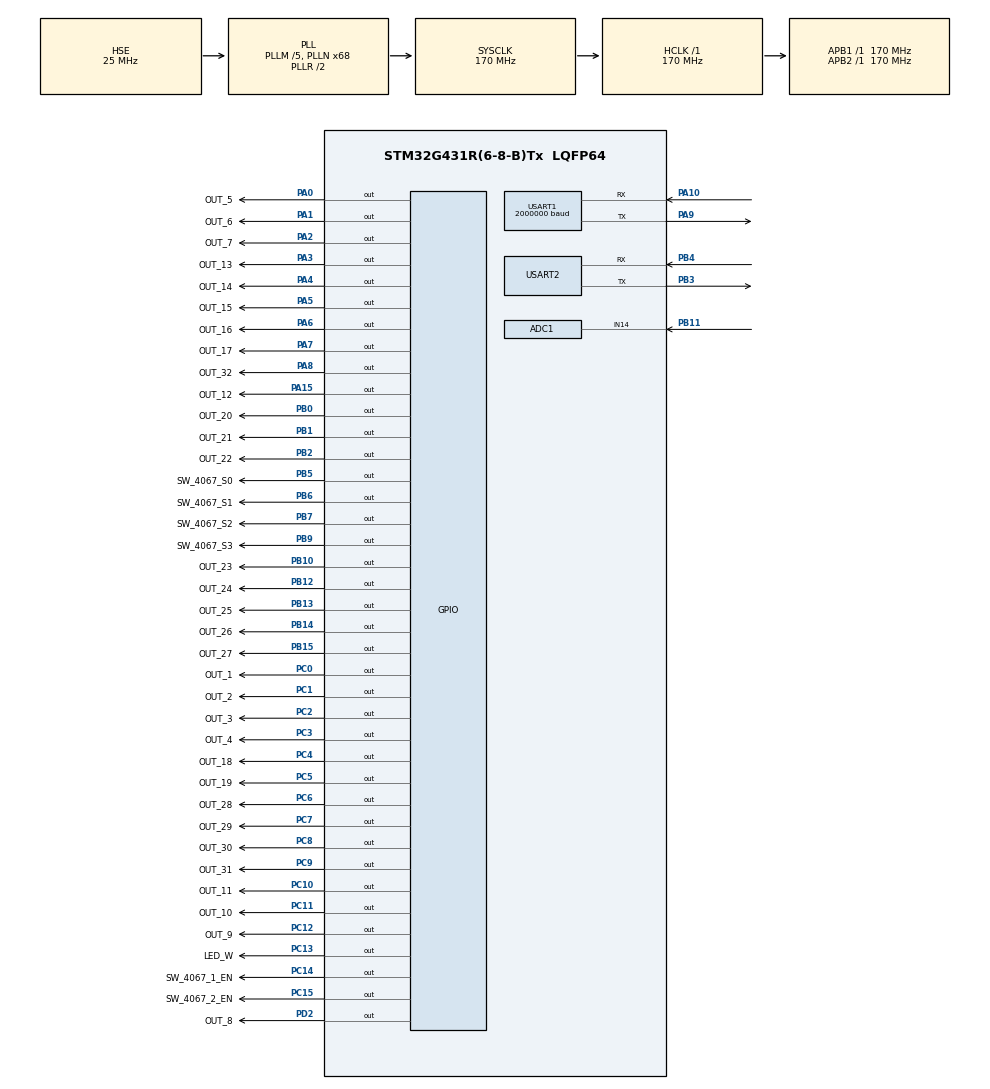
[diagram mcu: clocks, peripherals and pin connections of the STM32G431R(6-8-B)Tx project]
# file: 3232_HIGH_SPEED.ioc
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ADC1.Channel-0\#ChannelRegularConversion=ADC_CHANNEL_14
ADC1.ContinuousConvMode=ENABLE
ADC1.DMAContinuousRequests=ENABLE
ADC1.NbrOfConversionFlag=1
ADC1.OffsetNumber-0\#ChannelRegularConversion=ADC_OFFSET_NONE
ADC1.Rank-0\#ChannelRegularConversion=1
ADC1.Resolution=ADC_RESOLUTION_8B
ADC1.SamplingTime-0\#ChannelRegularConversion=ADC_SAMPLETIME_2CYCLES_5
ADC1.master=1
Dma.ADC1.3.Direction=DMA_PERIPH_TO_MEMORY
Dma.ADC1.3.EventEnable=DISABLE
Dma.ADC1.3.Instance=DMA1_Channel4
Dma.ADC1.3.MemDataAlignment=DMA_MDATAALIGN_BYTE
Dma.ADC1.3.MemInc=DMA_MINC_ENABLE
Dma.ADC1.3.Mode=DMA_CIRCULAR
Dma.ADC1.3.PeriphDataAlignment=DMA_PDATAALIGN_BYTE
Dma.ADC1.3.PeriphInc=DMA_PINC_DISABLE
Dma.ADC1.3.Polarity=HAL_DMAMUX_REQ_GEN_RISING
Dma.ADC1.3.Priority=DMA_PRIORITY_LOW
Dma.ADC1.3.RequestNumber=1
Dma.ADC1.3.SignalID=NONE
Dma.ADC1.3.SyncEnable=DISABLE
Dma.ADC1.3.SyncPolarity=HAL_DMAMUX_SYNC_NO_EVENT
Dma.ADC1.3.SyncRequestNumber=1
Dma.ADC1.3.SyncSignalID=NONE
Dma.Request0=USART2_RX
Dma.Request1=USART2_TX
Dma.Request2=USART1_TX
Dma.Request3=ADC1
Dma.USART1_TX.2.Direction=DMA_MEMORY_TO_PERIPH
Dma.USART1_TX.2.EventEnable=DISABLE
Dma.USART1_TX.2.Instance=DMA1_Channel3
Dma.USART1_TX.2.MemDataAlignment=DMA_MDATAALIGN_BYTE
Dma.USART1_TX.2.MemInc=DMA_MINC_ENABLE
Dma.USART1_TX.2.Mode=DMA_NORMAL
Dma.USART1_TX.2.PeriphDataAlignment=DMA_PDATAALIGN_BYTE
Dma.USART1_TX.2.PeriphInc=DMA_PINC_DISABLE
Dma.USART1_TX.2.Polarity=HAL_DMAMUX_REQ_GEN_RISING
Dma.USART1_TX.2.Priority=DMA_PRIORITY_LOW
Dma.USART1_TX.2.RequestNumber=1
Dma.USART1_TX.2.SignalID=NONE
Dma.USART1_TX.2.SyncEnable=DISABLE
Dma.USART1_TX.2.SyncPolarity=HAL_DMAMUX_SYNC_NO_EVENT
Dma.USART1_TX.2.SyncRequestNumber=1
Dma.USART1_TX.2.SyncSignalID=NONE
Dma.USART2_RX.0.Direction=DMA_PERIPH_TO_MEMORY
Dma.USART2_RX.0.EventEnable=DISABLE
Dma.USART2_RX.0.Instance=DMA1_Channel1
Dma.USART2_RX.0.MemDataAlignment=DMA_MDATAALIGN_BYTE
Dma.USART2_RX.0.MemInc=DMA_MINC_ENABLE
Dma.USART2_RX.0.Mode=DMA_NORMAL
Dma.USART2_RX.0.PeriphDataAlignment=DMA_PDATAALIGN_BYTE
Dma.USART2_RX.0.PeriphInc=DMA_PINC_DISABLE
Dma.USART2_RX.0.Polarity=HAL_DMAMUX_REQ_GEN_RISING
Dma.USART2_RX.0.Priority=DMA_PRIORITY_LOW
Dma.USART2_RX.0.RequestNumber=1
Dma.USART2_RX.0.SignalID=NONE
Dma.USART2_RX.0.SyncEnable=DISABLE
Dma.USART2_RX.0.SyncPolarity=HAL_DMAMUX_SYNC_NO_EVENT
Dma.USART2_RX.0.SyncRequestNumber=1
Dma.USART2_RX.0.SyncSignalID=NONE
Dma.USART2_TX.1.Direction=DMA_MEMORY_TO_PERIPH
Dma.USART2_TX.1.EventEnable=DISABLE
Dma.USART2_TX.1.Instance=DMA1_Channel2
Dma.USART2_TX.1.MemDataAlignment=DMA_MDATAALIGN_BYTE
Dma.USART2_TX.1.MemInc=DMA_MINC_ENABLE
Dma.USART2_TX.1.Mode=DMA_NORMAL
Dma.USART2_TX.1.PeriphDataAlignment=DMA_PDATAALIGN_BYTE
Dma.USART2_TX.1.PeriphInc=DMA_PINC_DISABLE
Dma.USART2_TX.1.Polarity=HAL_DMAMUX_REQ_GEN_RISING
Dma.USART2_TX.1.Priority=DMA_PRIORITY_LOW
Dma.USART2_TX.1.RequestNumber=1
Dma.USART2_TX.1.SignalID=NONE
Dma.USART2_TX.1.SyncEnable=DISABLE
Dma.USART2_TX.1.SyncPolarity=HAL_DMAMUX_SYNC_NO_EVENT
Dma.USART2_TX.1.SyncRequestNumber=1
Dma.USART2_TX.1.SyncSignalID=NONE
IWDG.Prescaler=IWDG_PRESCALER_128
Mcu.Family=STM32G4
Mcu.Name=STM32G431R(6-8-B)Tx
Mcu.Package=LQFP64
NVIC.DMA1_Channel1_IRQn=true\:0\:0\:false\:false\:true\:false\:true\:true
NVIC.DMA1_Channel2_IRQn=true\:0\:0\:false\:false\:true\:false\:true\:true
NVIC.DMA1_Channel3_IRQn=true\:0\:0\:false\:false\:true\:false\:true\:true
NVIC.DMA1_Channel4_IRQn=true\:0\:0\:false\:false\:true\:false\:true\:true
NVIC.PriorityGroup=NVIC_PRIORITYGROUP_4
NVIC.USART1_IRQn=true\:0\:0\:false\:false\:true\:false\:true\:true
NVIC.USART2_IRQn=true\:0\:0\:false\:false\:true\:false\:true\:true
PA0.GPIO_Label=OUT_5
PA0.GPIO_ModeDefaultOutputPP=GPIO_MODE_OUTPUT_PP
PA0.GPIO_PuPd=GPIO_NOPULL
PA0.GPIO_Speed=GPIO_SPEED_FREQ_VERY_HIGH
PA0.PinState=GPIO_PIN_RESET
PA0.Signal=GPIO_Output
PA1.GPIO_Label=OUT_6
PA1.GPIO_ModeDefaultOutputPP=GPIO_MODE_OUTPUT_PP
PA1.GPIO_PuPd=GPIO_NOPULL
PA1.GPIO_Speed=GPIO_SPEED_FREQ_VERY_HIGH
PA1.PinState=GPIO_PIN_RESET
PA1.Signal=GPIO_Output
PA10.GPIO_Speed=GPIO_SPEED_FREQ_VERY_HIGH
PA10.Mode=Asynchronous
PA10.Signal=USART1_RX
PA13.Mode=Serial_Wire
PA13.Signal=SYS_JTMS-SWDIO
PA14.Mode=Serial_Wire
PA14.Signal=SYS_JTCK-SWCLK
PA15.GPIO_Label=OUT_12
PA15.GPIO_ModeDefaultOutputPP=GPIO_MODE_OUTPUT_PP
PA15.GPIO_PuPd=GPIO_NOPULL
PA15.GPIO_Speed=GPIO_SPEED_FREQ_VERY_HIGH
PA15.PinState=GPIO_PIN_RESET
PA15.Signal=GPIO_Output
PA2.GPIO_Label=OUT_7
PA2.GPIO_ModeDefaultOutputPP=GPIO_MODE_OUTPUT_PP
PA2.GPIO_PuPd=GPIO_NOPULL
PA2.GPIO_Speed=GPIO_SPEED_FREQ_VERY_HIGH
PA2.PinState=GPIO_PIN_RESET
PA2.Signal=GPIO_Output
PA3.GPIO_Label=OUT_13
PA3.GPIO_ModeDefaultOutputPP=GPIO_MODE_OUTPUT_PP
PA3.GPIO_PuPd=GPIO_NOPULL
PA3.GPIO_Speed=GPIO_SPEED_FREQ_VERY_HIGH
PA3.PinState=GPIO_PIN_RESET
PA3.Signal=GPIO_Output
PA4.GPIO_Label=OUT_14
PA4.GPIO_ModeDefaultOutputPP=GPIO_MODE_OUTPUT_PP
PA4.GPIO_PuPd=GPIO_NOPULL
PA4.GPIO_Speed=GPIO_SPEED_FREQ_VERY_HIGH
PA4.PinState=GPIO_PIN_RESET
PA4.Signal=GPIO_Output
PA5.GPIO_Label=OUT_15
PA5.GPIO_ModeDefaultOutputPP=GPIO_MODE_OUTPUT_PP
PA5.GPIO_PuPd=GPIO_NOPULL
PA5.GPIO_Speed=GPIO_SPEED_FREQ_VERY_HIGH
PA5.PinState=GPIO_PIN_RESET
PA5.Signal=GPIO_Output
PA6.GPIO_Label=OUT_16
PA6.GPIO_ModeDefaultOutputPP=GPIO_MODE_OUTPUT_PP
PA6.GPIO_PuPd=GPIO_NOPULL
PA6.GPIO_Speed=GPIO_SPEED_FREQ_VERY_HIGH
PA6.PinState=GPIO_PIN_RESET
PA6.Signal=GPIO_Output
PA7.GPIO_Label=OUT_17
PA7.GPIO_ModeDefaultOutputPP=GPIO_MODE_OUTPUT_PP
PA7.GPIO_PuPd=GPIO_NOPULL
PA7.GPIO_Speed=GPIO_SPEED_FREQ_VERY_HIGH
PA7.PinState=GPIO_PIN_RESET
PA7.Signal=GPIO_Output
PA8.GPIO_Label=OUT_32
PA8.GPIO_ModeDefaultOutputPP=GPIO_MODE_OUTPUT_PP
PA8.GPIO_PuPd=GPIO_NOPULL
PA8.GPIO_Speed=GPIO_SPEED_FREQ_VERY_HIGH
PA8.PinState=GPIO_PIN_RESET
PA8.Signal=GPIO_Output
PA9.GPIO_Speed=GPIO_SPEED_FREQ_VERY_HIGH
PA9.Mode=Asynchronous
PA9.Signal=USART1_TX
PB0.GPIO_Label=OUT_20
PB0.GPIO_ModeDefaultOutputPP=GPIO_MODE_OUTPUT_PP
PB0.GPIO_PuPd=GPIO_NOPULL
PB0.GPIO_Speed=GPIO_SPEED_FREQ_VERY_HIGH
PB0.PinState=GPIO_PIN_RESET
PB0.Signal=GPIO_Output
PB1.GPIO_Label=OUT_21
PB1.GPIO_ModeDefaultOutputPP=GPIO_MODE_OUTPUT_PP
PB1.GPIO_PuPd=GPIO_NOPULL
PB1.GPIO_Speed=GPIO_SPEED_FREQ_VERY_HIGH
PB1.PinState=GPIO_PIN_RESET
PB1.Signal=GPIO_Output
PB10.GPIO_Label=OUT_23
PB10.GPIO_ModeDefaultOutputPP=GPIO_MODE_OUTPUT_PP
PB10.GPIO_PuPd=GPIO_NOPULL
PB10.GPIO_Speed=GPIO_SPEED_FREQ_VERY_HIGH
PB10.PinState=GPIO_PIN_RESET
PB10.Signal=GPIO_Output
PB11.Mode=IN14-Single-Ended
PB11.Signal=ADC1_IN14
PB12.GPIO_Label=OUT_24
PB12.GPIO_ModeDefaultOutputPP=GPIO_MODE_OUTPUT_PP
PB12.GPIO_PuPd=GPIO_NOPULL
PB12.GPIO_Speed=GPIO_SPEED_FREQ_VERY_HIGH
PB12.PinState=GPIO_PIN_RESET
PB12.Signal=GPIO_Output
PB13.GPIO_Label=OUT_25
PB13.GPIO_ModeDefaultOutputPP=GPIO_MODE_OUTPUT_PP
PB13.GPIO_PuPd=GPIO_NOPULL
PB13.GPIO_Speed=GPIO_SPEED_FREQ_VERY_HIGH
PB13.PinState=GPIO_PIN_RESET
PB13.Signal=GPIO_Output
PB14.GPIO_Label=OUT_26
PB14.GPIO_ModeDefaultOutputPP=GPIO_MODE_OUTPUT_PP
PB14.GPIO_PuPd=GPIO_NOPULL
PB14.GPIO_Speed=GPIO_SPEED_FREQ_VERY_HIGH
PB14.PinState=GPIO_PIN_RESET
PB14.Signal=GPIO_Output
PB15.GPIO_Label=OUT_27
PB15.GPIO_ModeDefaultOutputPP=GPIO_MODE_OUTPUT_PP
PB15.GPIO_PuPd=GPIO_NOPULL
PB15.GPIO_Speed=GPIO_SPEED_FREQ_VERY_HIGH
PB15.PinState=GPIO_PIN_RESET
PB15.Signal=GPIO_Output
PB2.GPIO_Label=OUT_22
PB2.GPIO_ModeDefaultOutputPP=GPIO_MODE_OUTPUT_PP
PB2.GPIO_PuPd=GPIO_NOPULL
PB2.GPIO_Speed=GPIO_SPEED_FREQ_VERY_HIGH
PB2.PinState=GPIO_PIN_RESET
PB2.Signal=GPIO_Output
PB3.GPIO_Speed=GPIO_SPEED_FREQ_VERY_HIGH
PB3.Mode=Asynchronous
PB3.Signal=USART2_TX
PB4.GPIO_Speed=GPIO_SPEED_FREQ_VERY_HIGH
PB4.Mode=Asynchronous
PB4.Signal=USART2_RX
PB5.GPIO_Label=SW_4067_S0
PB5.Signal=GPIO_Output
PB6.GPIO_Label=SW_4067_S1
PB6.Signal=GPIO_Output
PB7.GPIO_Label=SW_4067_S2
PB7.Signal=GPIO_Output
PB9.GPIO_Label=SW_4067_S3
PB9.Signal=GPIO_Output
PC0.GPIO_Label=OUT_1
PC0.GPIO_ModeDefaultOutputPP=GPIO_MODE_OUTPUT_PP
PC0.GPIO_PuPd=GPIO_NOPULL
PC0.GPIO_Speed=GPIO_SPEED_FREQ_VERY_HIGH
PC0.PinState=GPIO_PIN_RESET
PC0.Signal=GPIO_Output
PC1.GPIO_Label=OUT_2
PC1.GPIO_ModeDefaultOutputPP=GPIO_MODE_OUTPUT_PP
PC1.GPIO_PuPd=GPIO_NOPULL
PC1.GPIO_Speed=GPIO_SPEED_FREQ_VERY_HIGH
PC1.PinState=GPIO_PIN_RESET
PC1.Signal=GPIO_Output
PC10.GPIO_Label=OUT_11
PC10.GPIO_ModeDefaultOutputPP=GPIO_MODE_OUTPUT_PP
PC10.GPIO_PuPd=GPIO_NOPULL
PC10.GPIO_Speed=GPIO_SPEED_FREQ_VERY_HIGH
PC10.PinState=GPIO_PIN_RESET
PC10.Signal=GPIO_Output
PC11.GPIO_Label=OUT_10
PC11.GPIO_ModeDefaultOutputPP=GPIO_MODE_OUTPUT_PP
PC11.GPIO_PuPd=GPIO_NOPULL
PC11.GPIO_Speed=GPIO_SPEED_FREQ_VERY_HIGH
PC11.PinState=GPIO_PIN_RESET
PC11.Signal=GPIO_Output
PC12.GPIO_Label=OUT_9
PC12.GPIO_ModeDefaultOutputPP=GPIO_MODE_OUTPUT_PP
PC12.GPIO_PuPd=GPIO_NOPULL
PC12.GPIO_Speed=GPIO_SPEED_FREQ_VERY_HIGH
PC12.PinState=GPIO_PIN_RESET
PC12.Signal=GPIO_Output
PC13.GPIO_Label=LED_W
PC13.Signal=GPIO_Output
PC14-OSC32_IN.GPIO_Label=SW_4067_1_EN
PC14-OSC32_IN.Signal=GPIO_Output
PC15-OSC32_OUT.GPIO_Label=SW_4067_2_EN
PC15-OSC32_OUT.Signal=GPIO_Output
PC2.GPIO_Label=OUT_3
PC2.GPIO_ModeDefaultOutputPP=GPIO_MODE_OUTPUT_PP
PC2.GPIO_PuPd=GPIO_NOPULL
PC2.GPIO_Speed=GPIO_SPEED_FREQ_VERY_HIGH
PC2.PinState=GPIO_PIN_RESET
PC2.Signal=GPIO_Output
PC3.GPIO_Label=OUT_4
PC3.GPIO_ModeDefaultOutputPP=GPIO_MODE_OUTPUT_PP
PC3.GPIO_PuPd=GPIO_NOPULL
PC3.GPIO_Speed=GPIO_SPEED_FREQ_VERY_HIGH
PC3.PinState=GPIO_PIN_RESET
PC3.Signal=GPIO_Output
PC4.GPIO_Label=OUT_18
PC4.GPIO_ModeDefaultOutputPP=GPIO_MODE_OUTPUT_PP
PC4.GPIO_PuPd=GPIO_NOPULL
PC4.GPIO_Speed=GPIO_SPEED_FREQ_VERY_HIGH
PC4.PinState=GPIO_PIN_RESET
PC4.Signal=GPIO_Output
PC5.GPIO_Label=OUT_19
PC5.GPIO_ModeDefaultOutputPP=GPIO_MODE_OUTPUT_PP
PC5.GPIO_PuPd=GPIO_NOPULL
PC5.GPIO_Speed=GPIO_SPEED_FREQ_VERY_HIGH
PC5.PinState=GPIO_PIN_RESET
PC5.Signal=GPIO_Output
PC6.GPIO_Label=OUT_28
PC6.GPIO_ModeDefaultOutputPP=GPIO_MODE_OUTPUT_PP
PC6.GPIO_PuPd=GPIO_NOPULL
PC6.GPIO_Speed=GPIO_SPEED_FREQ_VERY_HIGH
PC6.PinState=GPIO_PIN_RESET
PC6.Signal=GPIO_Output
PC7.GPIO_Label=OUT_29
PC7.GPIO_ModeDefaultOutputPP=GPIO_MODE_OUTPUT_PP
PC7.GPIO_PuPd=GPIO_NOPULL
PC7.GPIO_Speed=GPIO_SPEED_FREQ_VERY_HIGH
PC7.PinState=GPIO_PIN_RESET
PC7.Signal=GPIO_Output
PC8.GPIO_Label=OUT_30
PC8.GPIO_ModeDefaultOutputPP=GPIO_MODE_OUTPUT_PP
PC8.GPIO_PuPd=GPIO_NOPULL
PC8.GPIO_Speed=GPIO_SPEED_FREQ_VERY_HIGH
PC8.PinState=GPIO_PIN_RESET
PC8.Signal=GPIO_Output
PC9.GPIO_Label=OUT_31
PC9.GPIO_ModeDefaultOutputPP=GPIO_MODE_OUTPUT_PP
PC9.GPIO_PuPd=GPIO_NOPULL
PC9.GPIO_Speed=GPIO_SPEED_FREQ_VERY_HIGH
PC9.PinState=GPIO_PIN_RESET
PC9.Signal=GPIO_Output
PD2.GPIO_Label=OUT_8
PD2.GPIO_ModeDefaultOutputPP=GPIO_MODE_OUTPUT_PP
PD2.GPIO_PuPd=GPIO_NOPULL
PD2.GPIO_Speed=GPIO_SPEED_FREQ_VERY_HIGH
PD2.PinState=GPIO_PIN_RESET
PD2.Signal=GPIO_Output
PF0-OSC_IN.Mode=HSE-External-Oscillator
PF0-OSC_IN.Signal=RCC_OSC_IN
PF1-OSC_OUT.Mode=HSE-External-Oscillator
PF1-OSC_OUT.Signal=RCC_OSC_OUT
ProjectManager.HeapSize=0x200
ProjectManager.StackSize=0x400
ProjectManager.TargetToolchain=MDK-ARM V5.32
RCC.ADC12Freq_Value=170000000
RCC.AHBFreq_Value=170000000
RCC.APB1Freq_Value=170000000
RCC.APB1TimFreq_Value=170000000
RCC.APB2Freq_Value=170000000
RCC.APB2TimFreq_Value=170000000
RCC.CortexFreq_Value=170000000
RCC.EXTERNAL_CLOCK_VALUE=12288000
RCC.HCLKFreq_Value=170000000
RCC.HSE_VALUE=25000000
RCC.HSI48_VALUE=48000000
RCC.HSI_VALUE=16000000
RCC.LSE_VALUE=32768
RCC.PLLM=RCC_PLLM_DIV5
RCC.PLLN=68
RCC.PLLSourceVirtual=RCC_PLLSOURCE_HSE
RCC.SYSCLKFreq_VALUE=170000000
RCC.SYSCLKSource=RCC_SYSCLKSOURCE_PLLCLK
RCC.USBFreq_Value=170000000
RCC.VCOOutputFreq_Value=340000000
USART1.BaudRate=2000000
USART1.VirtualMode-Asynchronous=VM_ASYNC
USART2.VirtualMode-Asynchronous=VM_ASYNC
VP_IWDG_VS_IWDG.Mode=IWDG_Activate
VP_SYS_VS_DBSignals.Mode=DisableDeadBatterySignals
board=custom

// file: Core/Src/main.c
/* USER CODE BEGIN Header */
/**
 ******************************************************************************
 * @file           : main.c
 * @brief          : Main program body
 ******************************************************************************
 * @attention
 *
 * Copyright (c) 2025 STMicroelectronics.
 * All rights reserved.
 *
 * This software is licensed under terms that can be found in the LICENSE file
 * in the root directory of this software component.
 * If no LICENSE file comes with this software, it is provided AS-IS.
 *
 ******************************************************************************
 */
/* USER CODE END Header */
#include "main.h"
#include "adc.h"
#include "dma.h"
#include "iwdg.h"
#include "usart.h"
#include "gpio.h"

/* USER CODE BEGIN Includes */
#include "user_comm.h"
/* USER CODE END Includes */

void SystemClock_Config(void);

int main(void)
{

    /* MCU Configuration--------------------------------------------------------*/

    /* Reset of all peripherals, Initializes the Flash interface and the Systick. */
    HAL_Init();

    /* Configure the system clock */
    SystemClock_Config();

    /* Initialize all configured peripherals */
    MX_GPIO_Init();
    MX_DMA_Init();
    MX_USART2_UART_Init();
    MX_USART1_UART_Init();
    MX_ADC1_Init();
    MX_IWDG_Init();
    /* USER CODE BEGIN 2 */
    delay_init();

    HAL_ADC_Start_DMA(&hadc1, (uint32_t *)sensor_adc_data, ADC_BUFFER_SIZE);

    /* USER CODE END 2 */

    /* Infinite loop */
    /* USER CODE BEGIN WHILE */
    while (1)
    {
        // 喂狗
        HAL_IWDG_Refresh(&hiwdg);

        // delay_ms(1000);
        main_adc_task();

        // HAL_Delay(100);
        // HAL_UART_Transmit(&huart1, (uint8_t *)"hello world\r\n", 13, HAL_MAX_DELAY);
        // printf("hello world\r\n");
        /* USER CODE END WHILE */

    }
}

void SystemClock_Config(void)
{
    RCC_OscInitTypeDef RCC_OscInitStruct = {0};
    RCC_ClkInitTypeDef RCC_ClkInitStruct = {0};

    /** Configure the main internal regulator output voltage
     */
    HAL_PWREx_ControlVoltageScaling(PWR_REGULATOR_VOLTAGE_SCALE1_BOOST);

    /** Initializes the RCC Oscillators according to the specified parameters
     * in the RCC_OscInitTypeDef structure.
     */
    RCC_OscInitStruct.OscillatorType = RCC_OSCILLATORTYPE_LSI | RCC_OSCILLATORTYPE_HSE;
    RCC_OscInitStruct.HSEState = RCC_HSE_ON;
    RCC_OscInitStruct.LSIState = RCC_LSI_ON;
    RCC_OscInitStruct.PLL.PLLState = RCC_PLL_ON;
    RCC_OscInitStruct.PLL.PLLSource = RCC_PLLSOURCE_HSE;
    RCC_OscInitStruct.PLL.PLLM = RCC_PLLM_DIV5;
    RCC_OscInitStruct.PLL.PLLN = 68;
    RCC_OscInitStruct.PLL.PLLP = RCC_PLLP_DIV2;
    RCC_OscInitStruct.PLL.PLLQ = RCC_PLLQ_DIV2;
    RCC_OscInitStruct.PLL.PLLR = RCC_PLLR_DIV2;
    if (HAL_RCC_OscConfig(&RCC_OscInitStruct) != HAL_OK)
    {
        Error_Handler();
    }

    /** Initializes the CPU, AHB and APB buses clocks
     */
    RCC_ClkInitStruct.ClockType = RCC_CLOCKTYPE_HCLK | RCC_CLOCKTYPE_SYSCLK | RCC_CLOCKTYPE_PCLK1 | RCC_CLOCKTYPE_PCLK2;
    RCC_ClkInitStruct.SYSCLKSource = RCC_SYSCLKSOURCE_PLLCLK;
    RCC_ClkInitStruct.AHBCLKDivider = RCC_SYSCLK_DIV1;
    RCC_ClkInitStruct.APB1CLKDivider = RCC_HCLK_DIV1;
    RCC_ClkInitStruct.APB2CLKDivider = RCC_HCLK_DIV1;

    if (HAL_RCC_ClockConfig(&RCC_ClkInitStruct, FLASH_LATENCY_4) != HAL_OK)
    {
        Error_Handler();
    }
}

void Error_Handler(void)
{
    __disable_irq();
    while (1)
    {
    }
}
